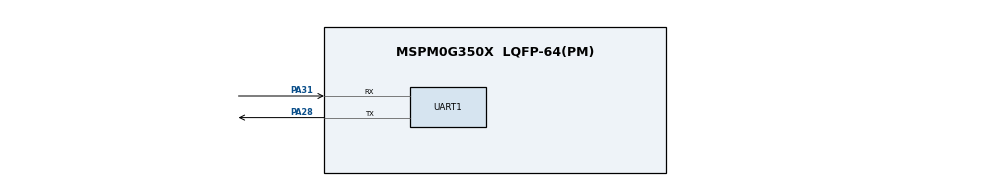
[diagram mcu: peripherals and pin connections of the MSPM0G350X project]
/**
 * @cliArgs --device "MSPM0G350X" --part "Default" --package "LQFP-64(PM)" --product "mspm0_sdk@2.10.00.04"
 * @versions {"tool":"1.26.2+4477"}
 */

/**
 * Import the modules used in this configuration.
 */
const GPIO   = scripting.addModule("/ti/driverlib/GPIO", {}, false);
const GPIO1  = GPIO.addInstance();
const GPIO2  = GPIO.addInstance();
const GPIO3  = GPIO.addInstance();
const GPIO4  = GPIO.addInstance();
const GPIO5  = GPIO.addInstance();
const GPIO6  = GPIO.addInstance();
const GPIO7  = GPIO.addInstance();
const GPIO8  = GPIO.addInstance();
const GPIO9  = GPIO.addInstance();
const GPIO10 = GPIO.addInstance();
const GPIO11 = GPIO.addInstance();
const GPIO12 = GPIO.addInstance();
const GPIO13 = GPIO.addInstance();
const SYSCTL = scripting.addModule("/ti/driverlib/SYSCTL");
const UART   = scripting.addModule("/ti/driverlib/UART", {}, false);
const UART1  = UART.addInstance();

/**
 * Write custom configuration values to the imported modules.
 */
GPIO1.$name                              = "OUT_1";
GPIO1.port                               = "PORTB";
GPIO1.portSegment                        = "Lower";
GPIO1.associatedPins[0].$name            = "PIN_1";
GPIO1.associatedPins[0].direction        = "INPUT";
GPIO1.associatedPins[0].assignedPin      = "1";
GPIO1.associatedPins[0].internalResistor = "PULL_DOWN";

const Board = scripting.addModule("/ti/driverlib/Board", {}, false);

GPIO2.$name                              = "OUT_2";
GPIO2.port                               = "PORTB";
GPIO2.portSegment                        = "Lower";
GPIO2.associatedPins[0].$name            = "PIN_2";
GPIO2.associatedPins[0].direction        = "INPUT";
GPIO2.associatedPins[0].assignedPin      = "2";
GPIO2.associatedPins[0].internalResistor = "PULL_UP";

GPIO3.$name                              = "OUT_3";
GPIO3.port                               = "PORTB";
GPIO3.portSegment                        = "Lower";
GPIO3.associatedPins[0].$name            = "PIN_3";
GPIO3.associatedPins[0].direction        = "INPUT";
GPIO3.associatedPins[0].assignedPin      = "3";
GPIO3.associatedPins[0].internalResistor = "PULL_UP";

GPIO4.$name                              = "OUT_4";
GPIO4.port                               = "PORTB";
GPIO4.portSegment                        = "Lower";
GPIO4.associatedPins[0].$name            = "PIN_4";
GPIO4.associatedPins[0].direction        = "INPUT";
GPIO4.associatedPins[0].assignedPin      = "4";
GPIO4.associatedPins[0].internalResistor = "PULL_UP";

GPIO5.$name                              = "OUT_5";
GPIO5.port                               = "PORTB";
GPIO5.portSegment                        = "Lower";
GPIO5.associatedPins[0].$name            = "PIN_5";
GPIO5.associatedPins[0].direction        = "INPUT";
GPIO5.associatedPins[0].assignedPin      = "5";
GPIO5.associatedPins[0].internalResistor = "PULL_UP";

GPIO6.$name                              = "OUT_6";
GPIO6.port                               = "PORTB";
GPIO6.portSegment                        = "Lower";
GPIO6.associatedPins[0].$name            = "PIN_6";
GPIO6.associatedPins[0].direction        = "INPUT";
GPIO6.associatedPins[0].assignedPin      = "6";
GPIO6.associatedPins[0].internalResistor = "PULL_UP";

GPIO7.$name                              = "OUT_7";
GPIO7.port                               = "PORTB";
GPIO7.portSegment                        = "Lower";
GPIO7.associatedPins[0].$name            = "PIN_7";
GPIO7.associatedPins[0].direction        = "INPUT";
GPIO7.associatedPins[0].assignedPin      = "7";
GPIO7.associatedPins[0].internalResistor = "PULL_UP";

GPIO8.$name                              = "OUT_8";
GPIO8.port                               = "PORTB";
GPIO8.portSegment                        = "Lower";
GPIO8.associatedPins[0].$name            = "PIN_8";
GPIO8.associatedPins[0].direction        = "INPUT";
GPIO8.associatedPins[0].assignedPin      = "8";
GPIO8.associatedPins[0].internalResistor = "PULL_UP";

GPIO9.$name                              = "OUT_9";
GPIO9.port                               = "PORTB";
GPIO9.portSegment                        = "Lower";
GPIO9.associatedPins[0].$name            = "PIN_9";
GPIO9.associatedPins[0].direction        = "INPUT";
GPIO9.associatedPins[0].assignedPin      = "9";
GPIO9.associatedPins[0].internalResistor = "PULL_UP";

GPIO10.$name                              = "OUT_10";
GPIO10.port                               = "PORTB";
GPIO10.portSegment                        = "Lower";
GPIO10.associatedPins[0].$name            = "PIN_10";
GPIO10.associatedPins[0].direction        = "INPUT";
GPIO10.associatedPins[0].assignedPin      = "10";
GPIO10.associatedPins[0].internalResistor = "PULL_UP";

GPIO11.$name                              = "OUT_11";
GPIO11.port                               = "PORTB";
GPIO11.portSegment                        = "Lower";
GPIO11.associatedPins[0].$name            = "PIN_11";
GPIO11.associatedPins[0].direction        = "INPUT";
GPIO11.associatedPins[0].assignedPin      = "11";
GPIO11.associatedPins[0].internalResistor = "PULL_UP";

GPIO12.$name                              = "OUT_12";
GPIO12.port                               = "PORTB";
GPIO12.portSegment                        = "Lower";
GPIO12.associatedPins[0].$name            = "PIN_12";
GPIO12.associatedPins[0].direction        = "INPUT";
GPIO12.associatedPins[0].assignedPin      = "12";
GPIO12.associatedPins[0].internalResistor = "PULL_UP";

GPIO13.port                          = "PORTB";
GPIO13.$name                         = "LED1";
GPIO13.associatedPins[0].assignedPin = "22";
GPIO13.associatedPins[0].$name       = "PIN_22";

SYSCTL.forceDefaultClkConfig = true;

UART1.$name                    = "UART_0";
UART1.peripheral.$assign       = "UART0";
UART1.peripheral.rxPin.$assign = "PA31";
UART1.peripheral.txPin.$assign = "PA28";
UART1.txPinConfig.$name        = "ti_driverlib_gpio_GPIOPinGeneric0";
UART1.rxPinConfig.$name        = "ti_driverlib_gpio_GPIOPinGeneric1";

/**
 * Pinmux solution for unlocked pins/peripherals. This ensures that minor changes to the automatic solver in a future
 * version of the tool will not impact the pinmux you originally saw.  These lines can be completely deleted in order to
 * re-solve from scratch.
 */
GPIO1.associatedPins[0].pin.$suggestSolution  = "PB1";
Board.peripheral.$suggestSolution             = "DEBUGSS";
Board.peripheral.swclkPin.$suggestSolution    = "PA20";
Board.peripheral.swdioPin.$suggestSolution    = "PA19";
GPIO2.associatedPins[0].pin.$suggestSolution  = "PB2";
GPIO3.associatedPins[0].pin.$suggestSolution  = "PB3";
GPIO4.associatedPins[0].pin.$suggestSolution  = "PB4";
GPIO5.associatedPins[0].pin.$suggestSolution  = "PB5";
GPIO6.associatedPins[0].pin.$suggestSolution  = "PB6";
GPIO7.associatedPins[0].pin.$suggestSolution  = "PB7";
GPIO8.associatedPins[0].pin.$suggestSolution  = "PB8";
GPIO9.associatedPins[0].pin.$suggestSolution  = "PB9";
GPIO10.associatedPins[0].pin.$suggestSolution = "PB10";
GPIO11.associatedPins[0].pin.$suggestSolution = "PB11";
GPIO12.associatedPins[0].pin.$suggestSolution = "PB12";
GPIO13.associatedPins[0].pin.$suggestSolution = "PB22";
SYSCTL.peripheral.$suggestSolution            = "SYSCTL";
